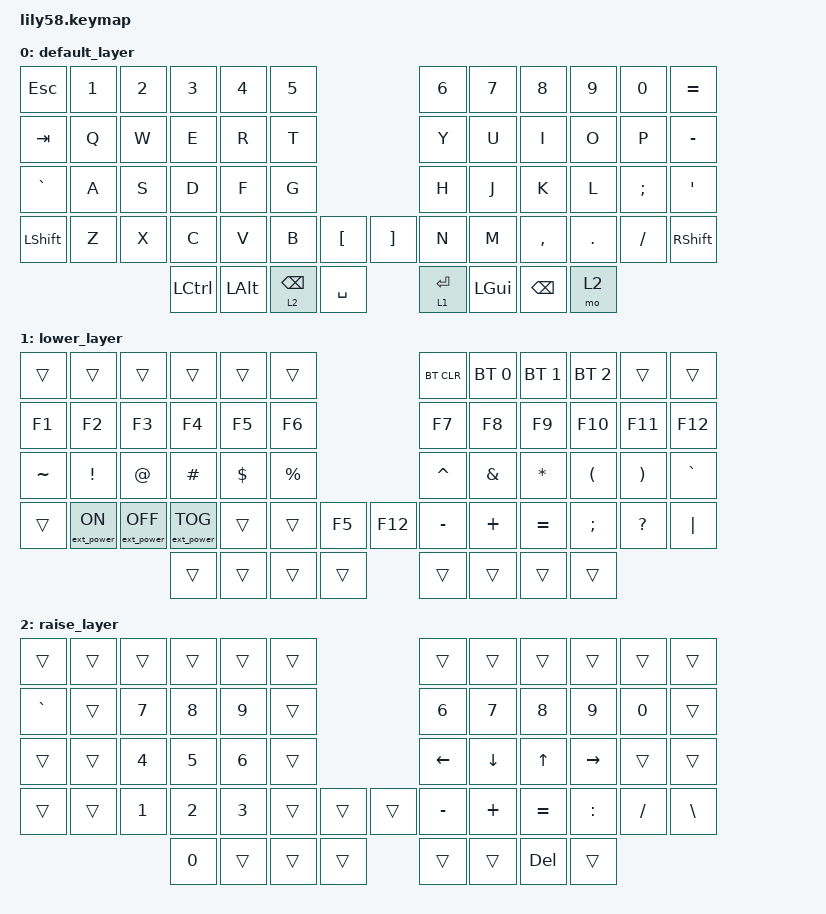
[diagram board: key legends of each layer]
/*
 * Copyright (c) 2020 The ZMK Contributors
 *
 * SPDX-License-Identifier: MIT
 */

#include <behaviors.dtsi>
#include <dt-bindings/zmk/keys.h>
#include <dt-bindings/zmk/bt.h>
#include <dt-bindings/zmk/ext_power.h>
#include <dt-bindings/zmk/behaviors.h>

/ {
    behaviors {
        // Custom layer tap example
        my_lt: custom_layer_tap {
            compatible = "zmk,behavior-hold-tap";
            #binding-cells = <2>;
            flavor = "tap-preferred";
            tapping-term-ms = <200>;
            quick-tap-ms = <125>;
            bindings = <&mo>, <&kp>;
        };
    };
    keymap {
        compatible = "zmk,keymap";

        default_layer {
            bindings = <
&kp ESC   &kp N1 &kp N2 &kp N3   &kp N4   &kp N5                     &kp N6 &kp N7   &kp N8    &kp N9  &kp N0   &kp EQUAL
&kp TAB   &kp Q  &kp W  &kp E    &kp R    &kp T                      &kp Y  &kp U    &kp I     &kp O   &kp P    &kp MINUS
&kp GRAVE &kp A  &kp S  &kp D    &kp F    &kp G                      &kp H  &kp J    &kp K     &kp L   &kp SEMI &kp SQT
&kp LSHFT &kp Z  &kp X  &kp C    &kp V    &kp B  &kp LBKT   &kp RBKT &kp N  &kp M    &kp COMMA &kp DOT &kp FSLH &kp RSHFT
                        &kp LCTRL &kp LALT&my_lt 2 BSPC  &kp SPACE &my_lt 1 RET &kp LGUI &kp BSPC &mo 2
            >;

            sensor-bindings = <&inc_dec_kp C_VOL_UP C_VOL_DN>;
        };

        lower_layer {
            bindings = <    
&trans     &trans           &trans            &trans            &trans       &trans                       &bt BT_CLR &bt BT_SEL 0     &bt BT_SEL 1      &bt BT_SEL 2      &trans       &trans 
&kp F1     &kp F2           &kp F3            &kp F4            &kp F5       &kp F6                       &kp F7     &kp F8    &kp F9    &kp F10   &kp F11   &kp F12
&kp TILDE  &kp EXCL         &kp AT            &kp HASH          &kp DOLLAR   &kp PRCNT                    &kp CARET &kp AMPS  &kp ASTRK &kp LPAR  &kp RPAR  &kp GRAVE
&trans     &ext_power EP_ON &ext_power EP_OFF &ext_power EP_TOG &trans       &trans    &kp F5   &kp F12   &kp MINUS &kp PLUS  &kp EQUAL &kp SEMI  &kp QMARK &kp PIPE
                                              &trans            &trans       &trans    &trans   &trans    &trans    &trans    &trans
            >;

            sensor-bindings = <&inc_dec_kp C_VOL_UP C_VOL_DN>;
        };

        raise_layer {
            bindings = <
&trans    &trans &trans &trans  &trans  &trans                      &trans      &trans    &trans    &trans    &trans    &trans
&kp GRAVE &trans &kp N7 &kp N8  &kp N9  &trans                      &kp N6      &kp N7    &kp N8    &kp N9    &kp N0    &trans
&trans    &trans &kp N4 &kp N5  &kp N6  &trans                      &kp LEFT    &kp DOWN  &kp UP    &kp RIGHT &trans    &trans
&trans    &trans &kp N1 &kp N2  &kp N3  &trans   &trans   &trans    &kp MINUS   &kp PLUS  &kp EQUAL &kp COLON &kp FSLH  &kp BSLH
                        &kp N0  &trans  &trans   &trans   &trans    &trans      &kp DEL   &trans
            >;

            sensor-bindings = <&inc_dec_kp C_VOL_UP C_VOL_DN>;
        };
    };
};
